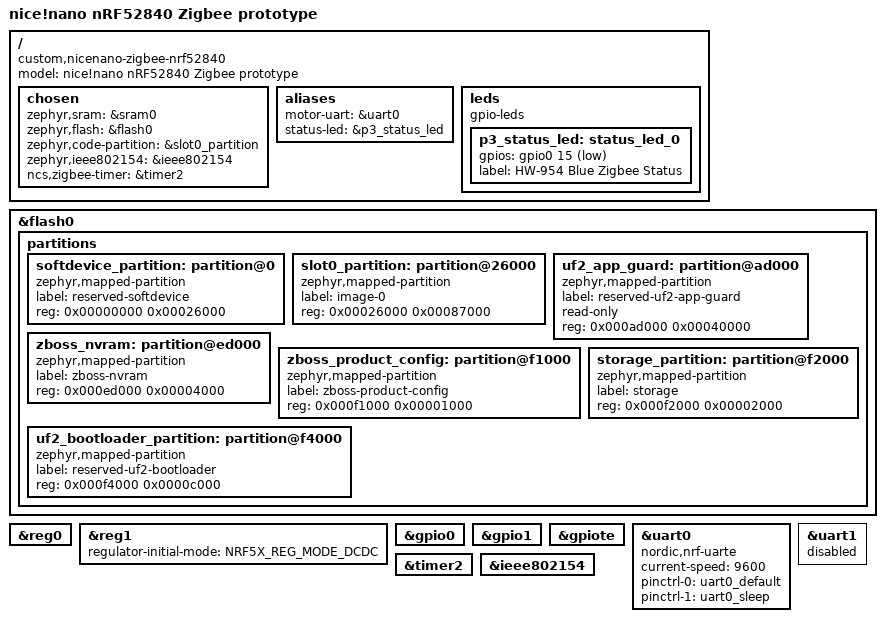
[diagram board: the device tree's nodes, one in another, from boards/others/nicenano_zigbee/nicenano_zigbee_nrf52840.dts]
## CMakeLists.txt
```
#
# Copyright (c) 2024 Nordic Semiconductor ASA
#
# SPDX-License-Identifier: LicenseRef-Nordic-5-Clause
#

cmake_minimum_required(VERSION 3.20.0)

find_package(Zephyr REQUIRED HINTS $ENV{ZEPHYR_BASE})

project("Zigbee application template")

# NORDIC SDK APP START
target_sources(app PRIVATE
  src/main.c
  src/tuya_frame.c
  src/tuya_motor.c
  src/tuya_motor_state.c
  src/p3_soft_uart.c
  src/tuya_uart_hybrid.c
)

target_include_directories(app PRIVATE include)
# NORDIC SDK APP END
```

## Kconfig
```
# P3 motor feature flags. All potentially dangerous actions OFF by default.
mainmenu "nice!nano Tuya P3 Zigbee blind"
source "Kconfig.zephyr"

menu "P3 prototype features"

config P3_UART_DIAGNOSTIC_OFF
    bool "Bench test: completely disable motor UART peripheral and workers"
    default n
    help
      Spare-board-only current measurement. Excludes UART worker sources
      and replaces motor communication with inert stubs.


config P3_UART_TX_ENABLE
    bool "ENABLE real Tuya P3 motor UART transmission (hardware test only)"
    default n
    help
      WARNING: Allows real motor movement from Zigbee commands.
      Only enable after validating pinout, supply, UART startup and
      safe end-stop behavior on the real P3 installation.
      Disabled by default even when the host tests succeed.

config P3_DIAG_STARTUP_QUERIES
    bool "Send four allowlisted P3 startup diagnostic UART requests ONCE"
    default n
    help
      Diagnostic-only physical UART TX with the movement command path OFF.
      Once after UART RX is ready, sends exactly four previously captured
      classic Tuya zero-data request frames: heartbeat 0x00, product 0x01,
      work mode 0x02, status query 0x08, in that order. No repeats, movement
      commands, target positions, STOP, Wi-Fi status, or Zigbee-triggered
      transmissions are possible in this diagnostic mode. Requires safe
      hardware-level UART 3.3 V, separate supplies, common GND and actual
      P3 TXD -> nRF P0.20 connected only for supervised bench testing.
      Choose this feature WITHOUT P3_UART_TX_ENABLE or P3_MCU_INIT_ENABLE.

config P3_MCU_INIT_ENABLE
    bool "Send captured WBR3 wake initialization (no motor motion)"
    depends on P3_UART_TX_ENABLE
    default n
    help
      Replays verified startup request opcodes after UART RX initialization:
      0x00 heartbeat, 0x01 product, 0x02 mode, 0x08 DP query.
      This does NOT send any motor movement or legacy Wi-Fi state.
      Repeated heartbeat intervals were not measured, so periodic polling
      is NOT implemented. Hardware startup reliability still untested.

config P3_ZCL_POSITION_ENABLE
    bool "Expose DP3 as current lift percentage (physical polarity to verify)"
    default n
    help
      Enables Zigbee CurrentPositionLiftPercentage updates based on DP3.
      Use only after confirming DP3 is a valid 0..100 position.\n      Verify physical open/closed orientation before treating the value as\n      calibrated; reporting is read-only and cannot move the motor.

config P3_POSITION_TARGET_ENABLE
    bool "Enable experimental DP2 percentage setpoint (supervised testing only)"
    depends on P3_UART_TX_ENABLE && P3_ZCL_POSITION_ENABLE
    default n
    help
      Allows Zigbee GoToLiftPercentage to send DP2 target values to P3.
      DP2 target behavior is not yet verified on physical P3 hardware.
      Enable only on the experimental blind, with working STOP and
      a clear path to stop motor movement. Does not calibrate motor limits.

config P3_HW_CALIBRATION_ENABLE
    bool "Enable supervised original P3 hardware limit calibration"
    depends on P3_UART_TX_ENABLE
    default n
    help
      Allows three captured Tuya commands: DP107=0 reset motor limits,
      DP102=0 start automatic ascent, DP102=1 stop and save upper limit.
      Only enable for supervised tests with physical stop/power disconnect
      accessible; resetting physical travel bounds may require re-training.

config P3_ZCL_POSITION_INVERT
    bool "Invert DP3 lift percentage and Zigbee requested setpoint"
    depends on P3_ZCL_POSITION_ENABLE
    default n
    help
      Zigbee Window Covering reports 0 percent as OPEN and 100 as CLOSED.
      Enable if actual DP3 is 0 percent CLOSED and 100 OPEN.

config P3_ZCL_BATTERY_ENABLE
    bool "Map DP13 to Zigbee Power Configuration battery percentage"
    default n
    help
      DP13=40 was observed while the battery displayed 40 percent.
      Separate runtime verification of source and calibration is required.
      Zigbee BatteryPercentageRemaining is half-percent units (40%=80).

endmenu
```

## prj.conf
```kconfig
#
# Zigbee window covering - battery End Device (not router).
# UART0 is reserved for future Tuya P3 bridge at 9600 baud.
#
CONFIG_NCS_SAMPLES_DEFAULTS=y

CONFIG_SERIAL=y
CONFIG_UART_INTERRUPT_DRIVEN=y
CONFIG_GPIO=y

CONFIG_CONSOLE=n
CONFIG_UART_CONSOLE=n

# v42.0-7: tickless System ON idle while preserving UART and Zigbee.
# CONFIG_PM is unavailable in the generated configuration of this SDK/board.
# Do not require Zephyr device/system PM for the first controlled measurement.
CONFIG_TICKLESS_KERNEL=y
CONFIG_LOG=n
CONFIG_PRINTK=n
CONFIG_BOOT_BANNER=n

CONFIG_HEAP_MEM_POOL_SIZE=2048
CONFIG_MAIN_THREAD_PRIORITY=7
CONFIG_SYSTEM_WORKQUEUE_STACK_SIZE=2048

CONFIG_ZIGBEE_ADD_ON=y
CONFIG_ZIGBEE_APP_UTILS=y
CONFIG_ZIGBEE_ROLE_END_DEVICE=y

# Pair exclusively with the user's Zigbee2MQTT coordinator (channel 11).
CONFIG_ZIGBEE_CHANNEL_SELECTION_MODE_SINGLE=y
CONFIG_ZIGBEE_CHANNEL=11

# No Nordic DK buttons/LEDs on nice!nano.
CONFIG_DK_LIBRARY=n

# Build 34: UART control with provisional DP13 battery percentage reporting.
# Build 35: experimental DP2 position targets enabled on the test blind only.
# v42.0-36: ONLY explicit Zigbee commands via independent UARTE1 TX.
# No TX on boot, no MCU queries, no calibration, no retry.
CONFIG_P3_UART_TX_ENABLE=y
# No automatic service/startup UART traffic.
CONFIG_P3_DIAG_STARTUP_QUERIES=n
CONFIG_P3_MCU_INIT_ENABLE=n
CONFIG_P3_ZCL_POSITION_ENABLE=y
CONFIG_P3_ZCL_POSITION_INVERT=n
CONFIG_P3_ZCL_BATTERY_ENABLE=y

# Supervised experimental test: DP2 target behavior is unverified.
# Restore position commands tested in stable v41.3.
CONFIG_P3_POSITION_TARGET_ENABLE=y

# Build 36 persistent software endpoints in reserved storage partition
CONFIG_FLASH=y
CONFIG_FLASH_MAP=y
CONFIG_NVS=y
CONFIG_SETTINGS=y
CONFIG_SETTINGS_NVS=y

# Build 37: opt-in hardware calibration captured from original WBR3
CONFIG_P3_HW_CALIBRATION_ENABLE=n

# v42.0-17: allow explicit device_deinit() for the one-shot UART test.
CONFIG_DEVICE_DEINIT_SUPPORT=y

# v42.0-19: device PM action API for UART0 suspend/resume experiment.
CONFIG_PM_DEVICE=y
```

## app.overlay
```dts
/*
 * Build 41 experimental local calibration button on P0.11.
 * Verify HW-954 solder-pad mapping before wiring. Never drive this input.
 * Contact (normally open) connects the selected pin to GND only.
 */
#include <zephyr/dt-bindings/gpio/gpio.h>

/ {
    p3_cal_key: p3_calibration_key {
        compatible = "gpio-keys";
        status = "okay";
        calibration_button: calibration_button {
            gpios = <&gpio0 11 (GPIO_PULL_UP | GPIO_ACTIVE_LOW)>;
            label = "P3 local calibration";
        };
    };
    aliases {
        calibration-button = &calibration_button;
    };
};

/* v42.0-16 diagnostic: keep UART0 enabled, but defer its driver init.
 * No device_init() call is made. Do not attach motor or UART wires.
 * Supported only if this Zephyr SDK recognizes zephyr,deferred-init.
 */
&uart0 {
    zephyr,deferred-init;
};
```

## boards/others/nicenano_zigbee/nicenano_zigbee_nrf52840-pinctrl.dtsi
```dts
#include <zephyr/dt-bindings/pinctrl/nrf-pinctrl.h>

&pinctrl {
    uart0_default: uart0_default {
        group1 {
            psels = <NRF_PSEL(UART_TX, 0, 20)>,
                    <NRF_PSEL(UART_RX, 0, 17)>;
            bias-pull-up;
        };
    };
    uart0_sleep: uart0_sleep {
        group1 {
            psels = <NRF_PSEL(UART_TX, 0, 20)>,
                    <NRF_PSEL(UART_RX, 0, 17)>;
            low-power-enable;
        };
    };
};
```

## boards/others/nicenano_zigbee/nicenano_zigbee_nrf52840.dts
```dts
/dts-v1/;
#include <nordic/nrf52840_qiaa.dtsi>
#include <zephyr/dt-bindings/gpio/gpio.h>
#include "nicenano_zigbee_nrf52840-pinctrl.dtsi"

/ {
    model = "nice!nano nRF52840 Zigbee prototype";
    compatible = "custom,nicenano-zigbee-nrf52840";

    chosen {
        zephyr,sram = &sram0;
        zephyr,flash = &flash0;
        zephyr,code-partition = &slot0_partition;
        zephyr,ieee802154 = &ieee802154;
        ncs,zigbee-timer = &timer2;
    };

    aliases {
        motor-uart = &uart0;
        status-led = &p3_status_led;
    };

    leds {
        compatible = "gpio-leds";
        /* nice!nano-compatible blue status LED, active-low on P0.15.
         * This is NOT the hardwired battery-charge indicator.
         */
        p3_status_led: status_led_0 {
            gpios = <&gpio0 15 GPIO_ACTIVE_LOW>;
            label = "HW-954 Blue Zigbee Status";
        };
    };
};

/*
 * DIAGNOSTIC FLASH LAYOUT ONLY — NOT VERIFIED AGAINST OUR UF2 BOOTLOADER.
 * Lower and upper bounds checked against Adafruit Bootloader 0.6.0:
 *   src/usb/uf2/uf2cfg.h USER_FLASH_END=0xAD000
 *   linker/nrf52840.ld bootloader start=0xF4000
 * Actual HW-954 ROM/UICR contents and vector handoff remain unverified.
 *
 *   0x00000-0x25fff  Existing S140 / reserved region
 *   0x26000-0xacfff  UF2-writeable application (Adafruit 0.6.0)
 *   0xad000-0xecfff  UF2 application guard (no firmware writes)
 *   0xed000-0xf3fff  7 preserved pages (28 KiB) in v0.6.0 DFU
 *   0xed000-0xf0fff  ZBOSS NVRAM (16 KiB)
 *   0xf1000-0xf1fff  ZBOSS production config
 *   0xf2000-0xf3fff  Zephyr settings storage (8 KiB)
 *   0xf4000-0xfffff  UF2 bootloader / reserved region
 *
 * Do not flash firmware built with this layout until the physical
 * board's bootloader, vector-table offset and memory map are verified.
 */
&flash0 {
    partitions {
        ranges;
        #address-cells = <1>;
        #size-cells = <1>;

        softdevice_partition: partition@0 {
            compatible = "zephyr,mapped-partition";
            label = "reserved-softdevice";
            reg = <0x00000000 0x00026000>;
        };

        slot0_partition: partition@26000 {
            compatible = "zephyr,mapped-partition";
            label = "image-0";
            reg = <0x00026000 0x00087000>;
        };

        /* Adafruit bootloader 0.6.0 explicitly limits APP writes to
         * target addresses strictly below 0xAD000 (uf2cfg.h).
         * DFU_APP_DATA_RESERVED=7*4096 protects 0xED000..0xF4000.
         * Do NOT let a linked firmware grow into this reserved gap.
         */
        uf2_app_guard: partition@ad000 {
            compatible = "zephyr,mapped-partition";
            label = "reserved-uf2-app-guard";
            read-only;
            reg = <0x000ad000 0x00040000>;
        };

        zboss_nvram: partition@ed000 {
            compatible = "zephyr,mapped-partition";
            label = "zboss-nvram";
            reg = <0x000ed000 0x00004000>;
        };

        zboss_product_config: partition@f1000 {
            compatible = "zephyr,mapped-partition";
            label = "zboss-product-config";
            reg = <0x000f1000 0x00001000>;
        };

        storage_partition: partition@f2000 {
            compatible = "zephyr,mapped-partition";
            label = "storage";
            reg = <0x000f2000 0x00002000>;
        };

        uf2_bootloader_partition: partition@f4000 {
            compatible = "zephyr,mapped-partition";
            label = "reserved-uf2-bootloader";
            reg = <0x000f4000 0x0000c000>;
        };
    };
};

&reg0 { status = "okay"; };
&reg1 { regulator-initial-mode = <NRF5X_REG_MODE_DCDC>; };
&gpio0 { status = "okay"; };
&gpio1 { status = "okay"; };
&gpiote { status = "okay"; };

&uart0 {
    compatible = "nordic,nrf-uarte";
    status = "okay";
    current-speed = <9600>;
    pinctrl-0 = <&uart0_default>;
    pinctrl-1 = <&uart0_sleep>;
    pinctrl-names = "default", "sleep";
};

/* v42.0-36: UARTE1 direct-register EasyDMA TX on P0.20.
 * Keep the Zephyr UART1 driver disabled: firmware owns this peripheral.
 */
&uart1 { status = "disabled"; };

&timer2 { status = "okay"; };
&ieee802154 { status = "okay"; };
```

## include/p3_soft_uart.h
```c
/* SPDX-License-Identifier: MIT */
#pragma once
#include <zephyr/kernel.h>
#include <stdint.h>
int p3_soft_uart_start(void);
void p3_soft_uart_stop(void);
int p3_soft_uart_read(uint8_t *byte, k_timeout_t timeout);
uint32_t p3_soft_uart_framing_errors(void);
uint32_t p3_soft_uart_overflows(void);
uint32_t p3_soft_uart_starts(void);
/* v42.0-34 hybrid software-first-byte / UARTE EasyDMA diagnostics. */
uint32_t p3_soft_uart_uarte_wakes(void);
uint32_t p3_soft_uart_dma_bytes(void);
uint32_t p3_soft_uart_handoff_errors(void);
uint32_t p3_soft_uart_hardware_errors(void);
/* v42.0-39, diagnostics only; no RX behavior/timing changes. */
uint32_t p3_soft_uart_software_nonheader_bytes(void);
uint32_t p3_soft_uart_last_hw_errorsrc(void);

/* v42.0-40 passive RX classification; DP1 supplied only from MCU reports. */
void p3_soft_uart_set_mcu_motion(uint8_t dp1);
uint32_t p3_soft_uart_reported_motion(void);
uint32_t p3_soft_uart_gpio_start_events(void);
uint32_t p3_soft_uart_last_gpio_start_ms(void);
uint32_t p3_soft_uart_gpio_starts_reported_idle(void);
uint32_t p3_soft_uart_gpio_starts_reported_moving(void);
uint32_t p3_soft_uart_gpio_starts_motion_unknown(void);
uint32_t p3_soft_uart_bad_stop_gpio(void);
uint32_t p3_soft_uart_bad_stop_chained(void);
uint32_t p3_soft_uart_bad_stop_reported_idle(void);
uint32_t p3_soft_uart_bad_stop_reported_moving(void);
uint32_t p3_soft_uart_bad_stop_motion_unknown(void);
uint32_t p3_soft_uart_last_bad_stop_ms(void);
uint32_t p3_soft_uart_last_bad_stop_byte(void);
```

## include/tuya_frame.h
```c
/* SPDX-License-Identifier: MIT */
#ifndef TUYA_FRAME_H_
#define TUYA_FRAME_H_

#include <stdbool.h>
#include <stddef.h>
#include <stdint.h>

/* Bounded parser for both Tuya MCU serial frame families. */
#define TUYA_MAX_DATA 128U
#define TUYA_MAX_FRAME (TUYA_MAX_DATA + 9U)

enum tuya_wire_format {
    TUYA_WIRE_CLASSIC = 0, /* 55 AA ver cmd len_hi len_lo data checksum */
    TUYA_WIRE_ZIGBEE = 2, /* 55 AA 02 seq_hi seq_lo cmd len_hi len_lo data checksum */
};

struct tuya_frame {
    enum tuya_wire_format format;
    uint8_t version;
    uint16_t sequence;
    uint8_t command;
    uint16_t length;
    uint8_t data[TUYA_MAX_DATA];
};

struct tuya_parser {
    uint8_t buffer[TUYA_MAX_FRAME];
    uint16_t used;
    uint16_t expected;
    uint32_t rejected;
};

struct tuya_dp {
    uint8_t id;
    uint8_t type;
    uint16_t length;
    const uint8_t *value;
};

typedef void (*tuya_dp_callback_t)(const struct tuya_dp *dp, void *user);

void tuya_parser_init(struct tuya_parser *parser);
bool tuya_parser_feed(struct tuya_parser *parser, uint8_t value,
                      struct tuya_frame *out);
bool tuya_foreach_report_dp(const struct tuya_frame *frame,
                            tuya_dp_callback_t callback, void *user);
bool tuya_dp_as_uint32(const struct tuya_dp *dp, uint32_t *value);

/* Encoder for host tests/future protocol integration; NOT wired to UART TX. */
size_t tuya_encode(const struct tuya_frame *frame, uint8_t *output,
                   size_t capacity);

#endif
```

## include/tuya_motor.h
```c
/* SPDX-License-Identifier: MIT */
#ifndef TUYA_MOTOR_H_
#define TUYA_MOTOR_H_

#include <stddef.h>
#include <stdint.h>

/* WBR3 -> P3 frames verified from the original motor's UART capture.
 * These functions ONLY encode bytes. They do not transmit anything.
 */
enum tuya_motor_action {
    TUYA_MOTOR_OPEN = 0,
    TUYA_MOTOR_STOP = 1,
    TUYA_MOTOR_CLOSE = 2,
};

/* OPEN/STOP/CLOSE, Tuya Classic protocol, DP1 enum 0/1/2. */
size_t tuya_motor_encode_action(enum tuya_motor_action action,
                                uint8_t *out, size_t capacity);

/* Position setpoint in 0..100, Tuya Classic protocol, DP2 Value type.
 * End-stop orientation is NOT yet confirmed. No transmission is performed.
 */
size_t tuya_motor_encode_position(uint8_t percent,
                                  uint8_t *out, size_t capacity);

/* Hardware calibration protocol captured from original WBR3 UART.
 * 1=reset limits (DP107=0); 2=start automatic training (DP102=0);
 * 3=finish and store upper limit (DP102=1).
 * Encodes only; does not transmit.
 */
size_t tuya_motor_encode_hw_calibration(uint8_t command,
                                       uint8_t *out, size_t capacity);

/* Original WBR3 -> P3 startup requests captured on motor wake.
 * These encoders NEVER send data; transmission stays gated by Kconfig.
 */
enum tuya_motor_request {
    TUYA_MOTOR_HEARTBEAT = 0x00,
    TUYA_MOTOR_PRODUCT_QUERY = 0x01,
    TUYA_MOTOR_WORK_MODE_QUERY = 0x02,
    TUYA_MOTOR_STATE_QUERY = 0x08,
};

size_t tuya_motor_encode_request(enum tuya_motor_request request,
                                 uint8_t *out, size_t capacity);

/* Hard allowlist for one-time Build 31 diagnostic TX. Valid indices 0..3,
 * always seven bytes, no DP or movement commands. Caller MUST NOT send
 * any other encoder's output in this diagnostic mode.
 */
#define TUYA_DIAGNOSTIC_STARTUP_STEPS 4U
size_t tuya_motor_encode_diag_startup_step(size_t index,
                                          uint8_t *out, size_t capacity);

/* Captured WBR3 network status 03 and 04, but neither is transmitted
 * automatically: Wi-Fi "cloud" state must not be invented for Zigbee.
 */
size_t tuya_motor_encode_legacy_network_status(uint8_t status,
                                               uint8_t *out, size_t capacity);

#endif
```

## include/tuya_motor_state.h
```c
/* SPDX-License-Identifier: MIT */
#ifndef TUYA_MOTOR_STATE_H_
#define TUYA_MOTOR_STATE_H_

#include "tuya_frame.h"

#include <stdbool.h>
#include <stdint.h>

/* Values observed from the ORIGINAL Tuya P3 UART, not from estimates. */
#define P3_DP_MOTION 1U
#define P3_DP_TARGET 2U
#define P3_DP_POSITION 3U
#define P3_DP_BATTERY 13U

struct tuya_motor_state {
    uint8_t motion;
    uint8_t position;
    uint8_t battery;
    bool motion_valid;
    bool position_valid;
    bool battery_valid;
    uint32_t report_count;
};

struct tuya_motor_changes {
    bool motion;
    bool position;
    bool battery;
};

/* Accept MCU-originated classic DP reports only (cmd=0x07, ver 0 or 3).
 * Wrong types, invalid lengths, invalid percentages, module-originated
 * commands and malformed multi-DP payloads NEVER change the state.
 */
bool tuya_motor_apply_report(const struct tuya_frame *frame,
                             struct tuya_motor_state *state,
                             struct tuya_motor_changes *changes);

#endif
```

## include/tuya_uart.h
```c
/* SPDX-License-Identifier: MIT */
#ifndef TUYA_UART_H_
#define TUYA_UART_H_

#include "tuya_motor.h"
#include "tuya_motor_state.h"

#include <stdbool.h>
#include <stdint.h>
#include "tuya_frame.h"

/* RX state is available; v42.0-36 enables user-only Zigbee TX via UARTE1.
 * True means accepted into a bounded UART queue, NOT physical completion.
 * Never auto-issue movement on boot or Zigbee network join.
 */
/* v42.0-36: hybrid RX thread publishes received MCU reports. */
void tuya_uart_set_rx_ready(bool ready);
void tuya_uart_note_rx_byte(void);
void tuya_uart_accept_report(const struct tuya_frame *frame);
void tuya_uart_set_rejected_count(uint32_t rejected);
void tuya_uart_mark_zigbee_command(void);
bool tuya_uart_submit_action(enum tuya_motor_action action);
bool tuya_uart_submit_position(uint8_t percent);
bool tuya_uart_submit_hw_calibration(uint8_t command);
void tuya_uart_get_state(struct tuya_motor_state *out);

/* UART RX-only telemetry. No interpretation of DP3/DP13 as calibrated
 * physical lift/battery levels is implied. Values reset on boot.
 */
struct tuya_uart_diagnostics {
    uint32_t rx_bytes;
    uint32_t tx_frames;
    uint32_t zigbee_commands;
    uint32_t local_finish_queued;
    uint32_t local_finish_transmitted;
    uint32_t local_finish_queue_to_tx_ms;
    uint32_t last_zigbee_to_tx_ms;
    uint32_t last_queue_to_tx_ms;
    uint32_t last_uart_tx_ms;
    uint32_t last_rx_after_tx_ms;
    uint32_t valid_frames;
    uint32_t rejected_frames;
    uint32_t dropped_bytes;
    uint32_t accepted_reports;
    uint8_t last_command;
    uint8_t last_format;
    uint8_t rx_ready;
    uint8_t diag_startup_requests_sent; /* 0..4; full 7-byte UART frames */
    uint8_t diag_startup_finished;      /* 1 after one-time attempt ends */
};

void tuya_uart_get_diagnostics(struct tuya_uart_diagnostics *out);
bool tuya_uart_submit_local_finish(void);

#endif
```

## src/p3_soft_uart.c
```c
/* SPDX-License-Identifier: MIT
 * v42.0-34 bench experiment: hybrid passive P3 RX, 9600 8N1.
 *
 * In low-power idle UARTE0 is DISABLED. GPIO P0.17 + TIMER3
 * decode the leading Tuya 0x55 byte. While TIMER3 samples the
 * first byte, UARTE0 is enabled but STARTRX is not triggered.
 * After a verified 0x55 stop bit, UARTE0 / EasyDMA take over
 * from the NEXT start bit (normally 0xAA), then stop after idle.
 *
 * The ~52 us UART handover was demonstrated on the user's HW-954
 * (v42.0-34/35); actual loss rate under motor activity is unproven.
 * Motor TX P0.20 is now physically connected and uses an INDEPENDENT
 * UARTE1 peripheral; this file owns only TIMER3 and UARTE0 RX.
 * Do not use as a production actuator until validated.
 */
#include <zephyr/kernel.h>
#include <errno.h>
#include <zephyr/device.h>
#include <zephyr/drivers/gpio.h>
#include <zephyr/irq.h>
#include <zephyr/sys/ring_buffer.h>
#include <zephyr/sys/atomic.h>
#include <zephyr/devicetree.h>
#include <hal/nrf_timer.h>
#include <hal/nrf_gpio.h>
#include <hal/nrf_uarte.h>
#include "p3_soft_uart.h"

#define P3_RX_PIN 17U
#define P3_RING_SIZE 2048U
#define P3_UART_DMA_SIZE 1024U
#define P3_BIT_US 104U
#define P3_FIRST_SAMPLE_US 156U
/* UARTE stays awake only while the frame is arriving, plus idle tail.
 * RXDRDY polling every 3 ms can extend this timeout by a few ms.
 */
#define P3_UART_IDLE_MS 15U
#define P3_UART_RXTO_WAIT_US 10000U
/* nRF52840 UARTE0: 9600 baud is 0x00275000 (Nordic PS register value). */
#define P3_UARTE_9600_REGISTER 0x00275000UL
#define P3_UARTE_ENABLE_REGISTER 8U
#define P3_PSEL_DISCONNECTED 0xFFFFFFFFUL

RING_BUF_DECLARE(p3_soft_ring, P3_RING_SIZE);
K_SEM_DEFINE(p3_soft_rx_sem, 0, 1);

static const struct device *const gpio = DEVICE_DT_GET(DT_NODELABEL(gpio0));
static struct gpio_callback rx_callback;
static uint8_t p3_dma_rx[P3_UART_DMA_SIZE] __aligned(4);
static atomic_t active;
static atomic_t uart_active;
static atomic_t framing_errors;
static atomic_t overflow_errors;
static atomic_t start_count;
static atomic_t uart_wake_count;
static atomic_t uart_dma_bytes;
static atomic_t uart_handoff_errors;
static atomic_t uart_hw_errors;
/* v42.0-39: read-only counters; no changes to IRQ timing or UART duty cycle. */
static atomic_t software_nonheader_bytes;
static atomic_t uart_hw_last_source;
/* v42.0-40: classify bad software STOP bits, never modify sampling timings.
 * DP1 is the last VALID report from the MCU: 0=open, 1=stop, 2=close.
 * 3=unknown until a valid DP1 is received; it is not a motion sensor.
 */
static atomic_t rx_reported_motion = ATOMIC_INIT(3);
static atomic_t rx_gpio_start_events;
static atomic_t rx_gpio_starts_reported_idle;
static atomic_t rx_gpio_starts_reported_moving;
static atomic_t rx_gpio_starts_motion_unknown;
static atomic_t rx_last_gpio_start_ms;
static atomic_t rx_bad_stop_gpio;
static atomic_t rx_bad_stop_chained;
static atomic_t rx_bad_stop_reported_idle;
static atomic_t rx_bad_stop_reported_moving;
static atomic_t rx_bad_stop_motion_unknown;
static atomic_t rx_last_bad_stop_ms;
static atomic_t rx_last_bad_stop_byte;
static volatile bool rx_origin_gpio;
static uint8_t shift_byte;
static uint8_t bit_index;
static bool uart_prepared;
static uint32_t uart_last_byte_ms;

enum p3_rx_phase {
    P3_RX_DATA,
    P3_RX_STOP,
    P3_RX_NEXT_START,
};
static volatile enum p3_rx_phase rx_phase;

static void p3_uart_disable(void)
{
    nrf_uarte_disable(NRF_UARTE0);
    uart_prepared = false;
}

/* Configuration is prepared at boot but the receive peripheral remains
 * disabled and has no DMA operation while P3 is quiet.
 * UART0 must remain Zephyr deferred-init; its driver cannot also own it.
 */
static void p3_uarte_prepare_registers(void)
{
    NRF_UARTE0->INTENCLR = 0xFFFFFFFFUL;
    nrf_uarte_disable(NRF_UARTE0);
    NRF_UARTE0->PSEL.TXD = P3_PSEL_DISCONNECTED;
    NRF_UARTE0->PSEL.RTS = P3_PSEL_DISCONNECTED;
    NRF_UARTE0->PSEL.CTS = P3_PSEL_DISCONNECTED;
    NRF_UARTE0->PSEL.RXD = P3_RX_PIN;
    NRF_UARTE0->CONFIG = 0U; /* parity excluded, HWFC disabled */
    NRF_UARTE0->BAUDRATE = P3_UARTE_9600_REGISTER;
    NRF_UARTE0->RXD.PTR = (uint32_t)(uintptr_t)p3_dma_rx;
    NRF_UARTE0->RXD.MAXCNT = sizeof(p3_dma_rx);
    NRF_UARTE0->EVENTS_RXSTARTED = 0U;
    NRF_UARTE0->EVENTS_RXDRDY = 0U;
    NRF_UARTE0->EVENTS_ENDRX = 0U;
    NRF_UARTE0->EVENTS_RXTO = 0U;
    NRF_UARTE0->EVENTS_ERROR = 0U;
}

/* Give hardware >0.8 ms to power up while TIMER3 reconstructs 0x55.
 * Do not start RX yet: a falling data bit within 0x55 could be mistaken
 * for a UART start bit and corrupt the following 0xAA byte.
 */
static void p3_uart_warmup(void)
{
    if (!uart_prepared && !atomic_get(&uart_active)) {
        NRF_UARTE0->RXD.PTR = (uint32_t)(uintptr_t)p3_dma_rx;
        NRF_UARTE0->RXD.MAXCNT = sizeof(p3_dma_rx);
        NRF_UARTE0->EVENTS_RXSTARTED = 0U;
        NRF_UARTE0->EVENTS_RXDRDY = 0U;
        NRF_UARTE0->EVENTS_ENDRX = 0U;
        NRF_UARTE0->EVENTS_RXTO = 0U;
        NRF_UARTE0->EVENTS_ERROR = 0U;
        NRF_UARTE0->ENABLE = P3_UARTE_ENABLE_REGISTER;
        uart_prepared = true;
    }
}

static void p3_uart_begin_dma(void)
{
    /* Called at software stop bit centre (9.5 UART bit intervals).
     * Only ~52 us until next start bit. Checking RXSTARTED later
     * is diagnostic; successful byte capture MUST be measured.
     */
    if (!uart_prepared) {
        atomic_inc(&uart_handoff_errors);
        return;
    }
    nrf_timer_task_trigger(NRF_TIMER3, NRF_TIMER_TASK_STOP);
    nrf_timer_int_disable(NRF_TIMER3, NRF_TIMER_INT_COMPARE0_MASK);
    (void)gpio_pin_interrupt_configure(gpio, P3_RX_PIN,
                                       GPIO_INT_DISABLE);
    atomic_set(&uart_active, 1);
    uart_last_byte_ms = k_uptime_get_32();
    atomic_inc(&uart_wake_count);
    NRF_UARTE0->TASKS_STARTRX = 1U;
}

static void timer3_irq(const void *unused)
{
    ARG_UNUSED(unused);
    if (!nrf_timer_event_check(NRF_TIMER3, NRF_TIMER_EVENT_COMPARE0)) {
        return;
    }
    nrf_timer_event_clear(NRF_TIMER3, NRF_TIMER_EVENT_COMPARE0);
    const bool level = nrf_gpio_pin_read(P3_RX_PIN) != 0;

    if (rx_phase == P3_RX_DATA) {
        if (bit_index == 0U) {
            atomic_inc(&start_count);
            p3_uart_warmup();
        }
        if (level) {
            shift_byte |= (uint8_t)(1U << bit_index);
        }
        bit_index++;
        if (bit_index == 8U) {
            rx_phase = P3_RX_STOP;
        }
        nrf_timer_cc_set(NRF_TIMER3, NRF_TIMER_CC_CHANNEL0,
                         P3_BIT_US);
        return;
    }

    if (rx_phase == P3_RX_STOP) {
        if (level) {
            if (ring_buf_put(&p3_soft_ring, &shift_byte, 1U) != 1U) {
                atomic_inc(&overflow_errors);
            } else {
                k_sem_give(&p3_soft_rx_sem);
            }
            /* Tuya 0x55 is the first header byte. UARTE now takes RX,
             * starting during its stop bit rather than inside data.
             */
            if (shift_byte == 0x55U) {
                p3_uart_begin_dma();
                return;
            }
            /* Count completed software bytes that are not a Tuya header,
             * without filtering or changing the proven receiver path.
             */
            atomic_inc(&software_nonheader_bytes);
        } else {
            /* Error-path-only sampling: classify before the existing
             * resynchronization behavior, leaving the 0x55 handoff fast.
             */
            atomic_inc(&framing_errors);
            if (rx_origin_gpio) {
                atomic_inc(&rx_bad_stop_gpio);
            } else {
                atomic_inc(&rx_bad_stop_chained);
            }
            const atomic_val_t motion = atomic_get(&rx_reported_motion);
            if (motion == 1) {
                atomic_inc(&rx_bad_stop_reported_idle);
            } else if (motion == 0 || motion == 2) {
                atomic_inc(&rx_bad_stop_reported_moving);
            } else {
                atomic_inc(&rx_bad_stop_motion_unknown);
            }
            atomic_set(&rx_last_bad_stop_byte, (atomic_val_t)shift_byte);
            atomic_set(&rx_last_bad_stop_ms, (atomic_val_t)k_uptime_get_32());
        }
        /* No 0x55 preamble: continue software sampling and keep
         * the hardware peripheral completely powered down.
         */
        if (uart_prepared) {
            p3_uart_disable();
        }
        rx_phase = P3_RX_NEXT_START;
        nrf_timer_cc_set(NRF_TIMER3, NRF_TIMER_CC_CHANNEL0,
                         P3_BIT_US);
        return;
    }

    if (!level) {
        /* Back-to-back software byte: already at middle of start bit. */
        shift_byte = 0U;
        bit_index = 0U;
        rx_phase = P3_RX_DATA;
        rx_origin_gpio = false; /* follow-on byte, not GPIO wake */
        nrf_timer_cc_set(NRF_TIMER3, NRF_TIMER_CC_CHANNEL0,
                         P3_BIT_US);
        return;
    }

    /* Idle while no valid preamble: return to GPIO edge detection. */
    nrf_timer_task_trigger(NRF_TIMER3, NRF_TIMER_TASK_STOP);
    nrf_timer_int_disable(NRF_TIMER3, NRF_TIMER_INT_COMPARE0_MASK);
    if (uart_prepared) {
        p3_uart_disable();
    }
    atomic_clear(&active);
}

static void rx_start_irq(const struct device *port,
                         struct gpio_callback *cb, gpio_port_pins_t pins)
{
    ARG_UNUSED(port);
    ARG_UNUSED(cb);
    ARG_UNUSED(pins);
    if (atomic_get(&uart_active) ||
        !atomic_cas(&active, 0, 1)) {
        return;
    }
    shift_byte = 0U;
    bit_index = 0U;
    rx_phase = P3_RX_DATA;
    rx_origin_gpio = true; /* tag byte whose start was a GPIO edge */
    nrf_timer_task_trigger(NRF_TIMER3, NRF_TIMER_TASK_CLEAR);
    nrf_timer_cc_set(NRF_TIMER3, NRF_TIMER_CC_CHANNEL0,
                     P3_FIRST_SAMPLE_US);
    nrf_timer_event_clear(NRF_TIMER3, NRF_TIMER_EVENT_COMPARE0);
    nrf_timer_int_enable(NRF_TIMER3, NRF_TIMER_INT_COMPARE0_MASK);
    nrf_timer_task_trigger(NRF_TIMER3, NRF_TIMER_TASK_START);
    /* Account AFTER arming TIMER3 so first-byte timing stays unchanged. */
    atomic_inc(&rx_gpio_start_events);
    atomic_set(&rx_last_gpio_start_ms, (atomic_val_t)k_uptime_get_32());
    const atomic_val_t motion = atomic_get(&rx_reported_motion);
    if (motion == 1) {
        atomic_inc(&rx_gpio_starts_reported_idle);
    } else if (motion == 0 || motion == 2) {
        atomic_inc(&rx_gpio_starts_reported_moving);
    } else {
        atomic_inc(&rx_gpio_starts_motion_unknown);
    }
}

static void p3_uarte_service(void)
{
    if (!atomic_get(&uart_active)) {
        return;
    }
    const uint32_t now = k_uptime_get_32();
    if (NRF_UARTE0->EVENTS_RXDRDY != 0U) {
        NRF_UARTE0->EVENTS_RXDRDY = 0U;
        uart_last_byte_ms = now;
    }
    if (NRF_UARTE0->EVENTS_ERROR != 0U) {
        NRF_UARTE0->EVENTS_ERROR = 0U;
        uint32_t cause = NRF_UARTE0->ERRORSRC;
        NRF_UARTE0->ERRORSRC = cause;
        atomic_set(&uart_hw_last_source, (atomic_val_t)cause);
        atomic_inc(&uart_hw_errors);
    }
    const bool buffer_full = NRF_UARTE0->EVENTS_ENDRX != 0U;
    if (!buffer_full &&
        (uint32_t)(now - uart_last_byte_ms) < P3_UART_IDLE_MS) {
        return;
    }

    NRF_UARTE0->EVENTS_RXTO = 0U;
    NRF_UARTE0->TASKS_STOPRX = 1U;
    bool rx_stopped = false;
    for (uint32_t elapsed = 0U;
         elapsed < P3_UART_RXTO_WAIT_US; elapsed += 10U) {
        if (NRF_UARTE0->EVENTS_RXTO != 0U) {
            rx_stopped = true;
            break;
        }
        k_busy_wait(10);
    }
    if (!rx_stopped) {
        atomic_inc(&uart_handoff_errors);
    } else {
        const uint32_t count = NRF_UARTE0->RXD.AMOUNT;
        if (count > 0U && count <= sizeof(p3_dma_rx)) {
            uint32_t copied = ring_buf_put(&p3_soft_ring,
                                            p3_dma_rx, count);
            atomic_add(&uart_dma_bytes, (atomic_val_t)copied);
            if (copied != count) {
                atomic_add(&overflow_errors,
                           (atomic_val_t)(count - copied));
            }
            if (copied > 0U) {
                k_sem_give(&p3_soft_rx_sem);
            }
        } else if (count > sizeof(p3_dma_rx)) {
            atomic_inc(&uart_handoff_errors);
        }
        if (NRF_UARTE0->EVENTS_RXSTARTED == 0U || count == 0U) {
            atomic_inc(&uart_handoff_errors);
        }
    }

    p3_uart_disable();
    atomic_clear(&uart_active);
    atomic_clear(&active);
    nrf_timer_task_trigger(NRF_TIMER3, NRF_TIMER_TASK_STOP);
    nrf_timer_event_clear(NRF_TIMER3, NRF_TIMER_EVENT_COMPARE0);
    nrf_timer_cc_set(NRF_TIMER3, NRF_TIMER_CC_CHANNEL0,
                     P3_FIRST_SAMPLE_US);
    rx_phase = P3_RX_DATA;
    shift_byte = 0U;
    bit_index = 0U;
    (void)gpio_pin_interrupt_configure(gpio, P3_RX_PIN,
                                       GPIO_INT_EDGE_FALLING);
}

int p3_soft_uart_start(void)
{
    if (!device_is_ready(gpio)) {
        return -ENODEV;
    }
    /* UART0 must have zephyr,deferred-init in DeviceTree. */
    p3_uarte_prepare_registers();
    int rc = gpio_pin_configure(gpio, P3_RX_PIN,
                                GPIO_INPUT | GPIO_PULL_UP);
    if (rc != 0) {
        return rc;
    }
    gpio_init_callback(&rx_callback, rx_start_irq, BIT(P3_RX_PIN));
    rc = gpio_add_callback(gpio, &rx_callback);
    if (rc != 0) {
        return rc;
    }
    nrf_timer_task_trigger(NRF_TIMER3, NRF_TIMER_TASK_STOP);
    nrf_timer_mode_set(NRF_TIMER3, NRF_TIMER_MODE_TIMER);
    nrf_timer_bit_width_set(NRF_TIMER3, NRF_TIMER_BIT_WIDTH_32);
    nrf_timer_prescaler_set(NRF_TIMER3, 4U);
    nrf_timer_shorts_enable(NRF_TIMER3,
                            NRF_TIMER_SHORT_COMPARE0_CLEAR_MASK);
    IRQ_CONNECT(TIMER3_IRQn, 3, timer3_irq, NULL, 0);
    irq_enable(TIMER3_IRQn);
    return gpio_pin_interrupt_configure(gpio, P3_RX_PIN,
                                        GPIO_INT_EDGE_FALLING);
}

void p3_soft_uart_stop(void)
{
    if (atomic_get(&uart_active)) {
        NRF_UARTE0->EVENTS_RXTO = 0U;
        NRF_UARTE0->TASKS_STOPRX = 1U;
        for (uint32_t elapsed = 0U;
             elapsed < P3_UART_RXTO_WAIT_US; elapsed += 10U) {
            if (NRF_UARTE0->EVENTS_RXTO != 0U) {
                break;
            }
            k_busy_wait(10);
        }
    }
    p3_uart_disable();
    atomic_clear(&uart_active);
    nrf_timer_task_trigger(NRF_TIMER3, NRF_TIMER_TASK_STOP);
    nrf_timer_int_disable(NRF_TIMER3, NRF_TIMER_INT_COMPARE0_MASK);
    (void)gpio_pin_interrupt_configure(gpio, P3_RX_PIN, GPIO_INT_DISABLE);
    atomic_clear(&active);
}

int p3_soft_uart_read(uint8_t *byte, k_timeout_t timeout)
{
    p3_uarte_service();
    if (ring_buf_get(&p3_soft_ring, byte, 1U) == 1U) {
        return 1;
    }
    /* Poll the UART event flags only while UARTE is on; in battery
     * idle, sleep normally for the caller's requested timeout.
     */
    k_timeout_t wait = atomic_get(&uart_active) ?
                       K_MSEC(3) : timeout;
    if (k_sem_take(&p3_soft_rx_sem, wait) != 0) {
        p3_uarte_service();
        return (int)ring_buf_get(&p3_soft_ring, byte, 1U);
    }
    p3_uarte_service();
    return (int)ring_buf_get(&p3_soft_ring, byte, 1U);
}

uint32_t p3_soft_uart_framing_errors(void)
{
    return (uint32_t)atomic_get(&framing_errors);
}
uint32_t p3_soft_uart_overflows(void)
{
    return (uint32_t)atomic_get(&overflow_errors);
}
uint32_t p3_soft_uart_starts(void)
{
    return (uint32_t)atomic_get(&start_count);
}
uint32_t p3_soft_uart_uarte_wakes(void)
{
    return (uint32_t)atomic_get(&uart_wake_count);
}
uint32_t p3_soft_uart_dma_bytes(void)
{
    return (uint32_t)atomic_get(&uart_dma_bytes);
}
uint32_t p3_soft_uart_handoff_errors(void)
{
    return (uint32_t)atomic_get(&uart_handoff_errors);
}
uint32_t p3_soft_uart_hardware_errors(void)
{
    return (uint32_t)atomic_get(&uart_hw_errors);
}
uint32_t p3_soft_uart_software_nonheader_bytes(void)
{
    return (uint32_t)atomic_get(&software_nonheader_bytes);
}
uint32_t p3_soft_uart_last_hw_errorsrc(void)
{
    return (uint32_t)atomic_get(&uart_hw_last_source);
}

/* Only accepted DP1 status reports may update classification; do not
 * fabricate a motor state from Zigbee command requests.
 */
void p3_soft_uart_set_mcu_motion(uint8_t dp1)
{
    if (dp1 <= 2U) {
        atomic_set(&rx_reported_motion, (atomic_val_t)dp1);
    }
}
uint32_t p3_soft_uart_reported_motion(void)
{
    return (uint32_t)atomic_get(&rx_reported_motion);
}
uint32_t p3_soft_uart_gpio_start_events(void)
{
    return (uint32_t)atomic_get(&rx_gpio_start_events);
}
uint32_t p3_soft_uart_last_gpio_start_ms(void)
{
    return (uint32_t)atomic_get(&rx_last_gpio_start_ms);
}
uint32_t p3_soft_uart_gpio_starts_reported_idle(void)
{
    return (uint32_t)atomic_get(&rx_gpio_starts_reported_idle);
}
uint32_t p3_soft_uart_gpio_starts_reported_moving(void)
{
    return (uint32_t)atomic_get(&rx_gpio_starts_reported_moving);
}
uint32_t p3_soft_uart_gpio_starts_motion_unknown(void)
{
    return (uint32_t)atomic_get(&rx_gpio_starts_motion_unknown);
}
uint32_t p3_soft_uart_bad_stop_gpio(void)
{
    return (uint32_t)atomic_get(&rx_bad_stop_gpio);
}
uint32_t p3_soft_uart_bad_stop_chained(void)
{
    return (uint32_t)atomic_get(&rx_bad_stop_chained);
}
uint32_t p3_soft_uart_bad_stop_reported_idle(void)
{
    return (uint32_t)atomic_get(&rx_bad_stop_reported_idle);
}
uint32_t p3_soft_uart_bad_stop_reported_moving(void)
{
    return (uint32_t)atomic_get(&rx_bad_stop_reported_moving);
}
uint32_t p3_soft_uart_bad_stop_motion_unknown(void)
{
    return (uint32_t)atomic_get(&rx_bad_stop_motion_unknown);
}
uint32_t p3_soft_uart_last_bad_stop_ms(void)
{
    return (uint32_t)atomic_get(&rx_last_bad_stop_ms);
}
uint32_t p3_soft_uart_last_bad_stop_byte(void)
{
    return (uint32_t)atomic_get(&rx_last_bad_stop_byte);
}
```

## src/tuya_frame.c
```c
/* SPDX-License-Identifier: MIT */
#include "tuya_frame.h"

#include <string.h>

void tuya_parser_init(struct tuya_parser *parser)
{
    memset(parser, 0, sizeof(*parser));
}

static void parser_reset(struct tuya_parser *parser, uint8_t last_byte)
{
    parser->used = 0;
    parser->expected = 0;
    parser->rejected++;
    if (last_byte == 0x55U) {
        parser->buffer[0] = last_byte;
        parser->used = 1;
    }
}

bool tuya_parser_feed(struct tuya_parser *parser, uint8_t byte,
                      struct tuya_frame *out)
{
    uint16_t header_size;
    uint16_t length_offset;
    uint16_t payload_length;
    uint16_t expected;
    uint16_t i;
    uint8_t sum = 0;

    if (parser->used == 0U) {
        if (byte == 0x55U) {
            parser->buffer[0] = byte;
            parser->used = 1;
        }
        return false;
    }

    if (parser->used == 1U) {
        if (byte == 0xaaU) {
            parser->buffer[1] = byte;
            parser->used = 2;
        } else if (byte != 0x55U) {
            parser_reset(parser, byte);
        }
        return false;
    }

    if (parser->used >= TUYA_MAX_FRAME) {
        parser_reset(parser, byte);
        return false;
    }
    parser->buffer[parser->used++] = byte;

    if (parser->used < 3U) {
        return false;
    }
    /* Version 0x02 denotes Tuya Zigbee-MCU framing with 16-bit sequence. */
    header_size = parser->buffer[2] == 0x02U ? 8U : 6U;
    length_offset = (uint16_t)(header_size - 2U);

    if (parser->used == header_size) {
        payload_length = (uint16_t)(((uint16_t)parser->buffer[length_offset] << 8) |
                                     parser->buffer[length_offset + 1U]);
        if (payload_length > TUYA_MAX_DATA) {
            parser_reset(parser, byte);
            return false;
        }
        parser->expected = (uint16_t)(header_size + payload_length + 1U);
    }

    expected = parser->expected;
    if (expected == 0U || parser->used < expected) {
        return false;
    }
    if (parser->used != expected) {
        parser_reset(parser, byte);
        return false;
    }

    for (i = 0; i < expected - 1U; ++i) {
        sum = (uint8_t)(sum + parser->buffer[i]);
    }
    if (sum != parser->buffer[expected - 1U]) {
        parser_reset(parser, byte);
        return false;
    }

    out->format = header_size == 8U ? TUYA_WIRE_ZIGBEE : TUYA_WIRE_CLASSIC;
    out->version = parser->buffer[2];
    out->sequence = header_size == 8U ?
        (uint16_t)(((uint16_t)parser->buffer[3] << 8) | parser->buffer[4]) : 0U;
    out->command = parser->buffer[header_size - 3U];
    out->length = (uint16_t)(expected - header_size - 1U);
    if (out->length > 0U) {
        memcpy(out->data, &parser->buffer[header_size], out->length);
    }
    parser->used = 0U;
    parser->expected = 0U;
    return true;
}

static bool is_dp_report(const struct tuya_frame *frame)
{
    if (frame->format == TUYA_WIRE_ZIGBEE) {
        /* Tuya Zigbee UART v0x02 DP commands, both directions.
         * 0x04: module->MCU set; 0x05: MCU response;
         * 0x06/0x2c: MCU reports; 0x2a: group; 0x27: advertising.
         * Acknowledgment frames of length 0/1 are not DP structures.
         */
        return frame->command == 0x04U || frame->command == 0x05U ||
               frame->command == 0x06U || frame->command == 0x27U ||
               frame->command == 0x2aU || frame->command == 0x2cU;
    }
    /* Classic Tuya UART: 0x06 set and 0x07 MCU DP report. */
    return frame->command == 0x06U || frame->command == 0x07U;
}

bool tuya_foreach_report_dp(const struct tuya_frame *frame,
                            tuya_dp_callback_t callback, void *user)
{
    size_t offset = 0;
    size_t remaining;
    size_t length;
    int pass;

    if (!is_dp_report(frame) || !callback || frame->length > TUYA_MAX_DATA) {
        return false;
    }
    /* Validate whole payload before delivering any DP value. */
    for (pass = 0; pass < 2; ++pass) {
        offset = 0;
        while (offset < frame->length) {
            struct tuya_dp dp;
            remaining = (size_t)frame->length - offset;
            if (remaining < 4U) {
                return false;
            }
            length = ((size_t)frame->data[offset + 2U] << 8) |
                      frame->data[offset + 3U];
            if (length > remaining - 4U) {
                return false;
            }
            dp.id = frame->data[offset];
            dp.type = frame->data[offset + 1U];
            dp.length = (uint16_t)length;
            dp.value = &frame->data[offset + 4U];
            if (pass == 1) {
                callback(&dp, user);
            }
            offset += 4U + length;
        }
    }
    return true;
}

bool tuya_dp_as_uint32(const struct tuya_dp *dp, uint32_t *value)
{
    if (dp->type == 0x02U && dp->length == 4U) {
        *value = ((uint32_t)dp->value[0] << 24) |
                 ((uint32_t)dp->value[1] << 16) |
                 ((uint32_t)dp->value[2] << 8) | dp->value[3];
        return true;
    }
    if ((dp->type == 0x04U || dp->type == 0x01U) && dp->length == 1U) {
        *value = dp->value[0];
        return true;
    }
    return false;
}

size_t tuya_encode(const struct tuya_frame *frame, uint8_t *output,
                   size_t capacity)
{
    size_t header_size = frame->format == TUYA_WIRE_ZIGBEE ? 8U : 6U;
    size_t full_size = header_size + frame->length + 1U;
    size_t i;
    uint8_t sum = 0U;

    if (frame->length > TUYA_MAX_DATA || capacity < full_size ||
        (frame->format != TUYA_WIRE_CLASSIC && frame->format != TUYA_WIRE_ZIGBEE)) {
        return 0U;
    }
    output[0] = 0x55U;
    output[1] = 0xaaU;
    output[2] = frame->version;
    if (frame->format == TUYA_WIRE_ZIGBEE) {
        if (frame->version != 0x02U) {
            return 0U;
        }
        output[3] = (uint8_t)(frame->sequence >> 8);
        output[4] = (uint8_t)frame->sequence;
    } else if (frame->version == 0x02U) {
        return 0U;
    }
    output[header_size - 3U] = frame->command;
    output[header_size - 2U] = (uint8_t)(frame->length >> 8);
    output[header_size - 1U] = (uint8_t)frame->length;
    if (frame->length > 0U) {
        memcpy(&output[header_size], frame->data, frame->length);
    }
    for (i = 0; i < full_size - 1U; ++i) {
        sum = (uint8_t)(sum + output[i]);
    }
    output[full_size - 1U] = sum;
    return full_size;
}
```

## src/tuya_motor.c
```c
/* SPDX-License-Identifier: MIT */
#include "tuya_motor.h"
#include "tuya_frame.h"

#include <string.h>

#define TUYA_CLASSIC_CONTROL_COMMAND 0x06U
#define TUYA_DP_ACTION 0x01U
#define TUYA_DP_POSITION_TARGET 0x02U
#define TUYA_TYPE_ENUM 0x04U
#define TUYA_TYPE_VALUE 0x02U

size_t tuya_motor_encode_action(enum tuya_motor_action action,
                                uint8_t *out, size_t capacity)
{
    struct tuya_frame packet = {0};

    if (out == NULL || action < TUYA_MOTOR_OPEN || action > TUYA_MOTOR_CLOSE) {
        return 0U;
    }

    packet.format = TUYA_WIRE_CLASSIC;
    packet.version = 0x00U;
    packet.command = TUYA_CLASSIC_CONTROL_COMMAND;
    packet.length = 5U;
    packet.data[0] = TUYA_DP_ACTION;
    packet.data[1] = TUYA_TYPE_ENUM;
    packet.data[2] = 0U;
    packet.data[3] = 1U;
    packet.data[4] = (uint8_t)action;
    return tuya_encode(&packet, out, capacity);
}

size_t tuya_motor_encode_position(uint8_t percent,
                                  uint8_t *out, size_t capacity)
{
    struct tuya_frame packet = {0};

    if (out == NULL || percent > 100U) {
        return 0U;
    }

    packet.format = TUYA_WIRE_CLASSIC;
    packet.version = 0x00U;
    packet.command = TUYA_CLASSIC_CONTROL_COMMAND;
    packet.length = 8U;
    packet.data[0] = TUYA_DP_POSITION_TARGET;
    packet.data[1] = TUYA_TYPE_VALUE;
    packet.data[2] = 0U;
    packet.data[3] = 4U;
    packet.data[4] = 0U;
    packet.data[5] = 0U;
    packet.data[6] = 0U;
    packet.data[7] = percent;
    return tuya_encode(&packet, out, capacity);
}

size_t tuya_motor_encode_hw_calibration(uint8_t command,
                                       uint8_t *out, size_t capacity)
{
    struct tuya_frame packet = {0};
    if (!out || command < 1U || command > 3U) return 0U;
    packet.format = TUYA_WIRE_CLASSIC;
    packet.version = 0U;
    packet.command = TUYA_CLASSIC_CONTROL_COMMAND;
    packet.length = 5U;
    packet.data[0] = (command == 1U) ? 0x6bU : 0x66U;
    packet.data[1] = TUYA_TYPE_ENUM;
    packet.data[2] = 0U;
    packet.data[3] = 1U;
    packet.data[4] = (command == 3U) ? 1U : 0U;
    return tuya_encode(&packet, out, capacity);
}

size_t tuya_motor_encode_request(enum tuya_motor_request request,
                                 uint8_t *out, size_t capacity)
{
    struct tuya_frame packet = {0};

    if (!out || (request != TUYA_MOTOR_HEARTBEAT &&
                 request != TUYA_MOTOR_PRODUCT_QUERY &&
                 request != TUYA_MOTOR_WORK_MODE_QUERY &&
                 request != TUYA_MOTOR_STATE_QUERY)) {
        return 0U;
    }

    packet.format = TUYA_WIRE_CLASSIC;
    packet.version = 0;
    packet.command = (uint8_t)request;
    packet.length = 0;
    return tuya_encode(&packet, out, capacity);
}

size_t tuya_motor_encode_diag_startup_step(size_t index,
                                          uint8_t *out, size_t capacity)
{
    static const enum tuya_motor_request allowlist[TUYA_DIAGNOSTIC_STARTUP_STEPS] = {
        TUYA_MOTOR_HEARTBEAT,
        TUYA_MOTOR_PRODUCT_QUERY,
        TUYA_MOTOR_WORK_MODE_QUERY,
        TUYA_MOTOR_STATE_QUERY
    };

    if (index >= TUYA_DIAGNOSTIC_STARTUP_STEPS || out == NULL) {
        return 0U;
    }
    return tuya_motor_encode_request(allowlist[index], out, capacity);
}

size_t tuya_motor_encode_legacy_network_status(uint8_t status,
                                               uint8_t *out, size_t capacity)
{
    struct tuya_frame packet = {0};

    /* Only the two values captured from original WBR3 are supported. */
    if (!out || (status != 3U && status != 4U)) {
        return 0U;
    }

    packet.format = TUYA_WIRE_CLASSIC;
    packet.version = 0;
    packet.command = 0x03U;
    packet.length = 1U;
    packet.data[0] = status;
    return tuya_encode(&packet, out, capacity);
}
```

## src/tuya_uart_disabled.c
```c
/* v42.0-11: no UART device, RX IRQ, or UART worker threads. */
#include "tuya_uart.h"
#include <string.h>
#include <zephyr/kernel.h>
#include <zephyr/sys/atomic.h>

static atomic_t command_count;

void tuya_uart_mark_zigbee_command(void)
{
    atomic_inc(&command_count);
}

bool tuya_uart_submit_action(enum tuya_motor_action action)
{
    (void)action;
    return false;
}

bool tuya_uart_submit_position(uint8_t percent)
{
    (void)percent;
    return false;
}

bool tuya_uart_submit_hw_calibration(uint8_t command)
{
    (void)command;
    return false;
}

bool tuya_uart_submit_local_finish(void)
{
    return false;
}

void tuya_uart_get_state(struct tuya_motor_state *out)
{
    if (out != NULL) {
        memset(out, 0, sizeof(*out));
    }
}

void tuya_uart_get_diagnostics(struct tuya_uart_diagnostics *out)
{
    if (out != NULL) {
        memset(out, 0, sizeof(*out));
        out->last_command = 0xffU;
        out->last_format = 0xffU;
        out->zigbee_commands = (uint32_t)atomic_get(&command_count);
    }
}
```
